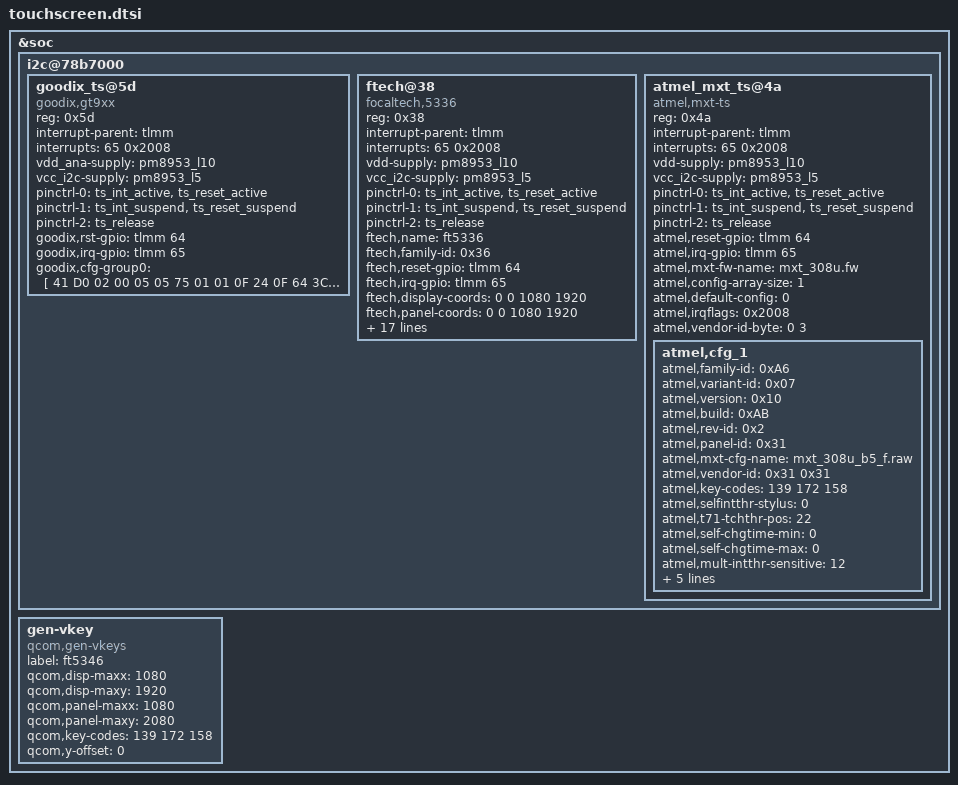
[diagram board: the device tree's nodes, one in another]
&soc{
    i2c@78b7000 { /* BLSP1 QUP3 */
		/delete-node/ synaptics@4b;
		goodix_ts@5d {
			compatible = "goodix,gt9xx";
			reg = <0x5d>;	
			interrupt-parent = <&tlmm>;
			interrupts = <65 0x2008>;
			vdd_ana-supply = <&pm8953_l10>;
			vcc_i2c-supply = <&pm8953_l5>;
			pinctrl-names = "pmx_ts_active","pmx_ts_suspend",
                        "pmx_ts_release";
                        pinctrl-0 = <&ts_int_active &ts_reset_active>;
                        pinctrl-1 = <&ts_int_suspend &ts_reset_suspend>;
                        pinctrl-2 = <&ts_release>;
			goodix,rst-gpio = <&tlmm 64 0x00>;
			goodix,irq-gpio = <&tlmm 65 0x2008>;
			goodix,cfg-group0 = [
				41 D0 02 00 05 05 75 01 01 0F 24 
				0F 64 3C 03 05 00 00 00 02 00 00 
				00 16 19 1C 14 8C 0E 0E 24 00 31 
				0D 00 00 00 83 33 1D 00 41 00 00 
				00 00 00 08 0A 00 2B 1C 3C 94 D5 
				03 08 00 00 04 93 1E 00 82 23 00 
				74 29 00 69 2F 00 5F 37 00 5F 20 
				40 60 00 F0 40 30 55 50 27 00 00 
				00 00 00 00 00 00 00 00 00 00 00 
				00 00 00 00 00 00 00 14 19 00 00 
				50 50 02 04 06 08 0A 0C 0E 10 12 
				14 16 18 1A 1C 00 00 00 00 00 00 
				00 00 00 00 00 00 00 00 00 00 1D 
				1E 1F 20 21 22 24 26 28 29 2A 1C 
				18 16 14 13 12 10 0F 0C 0A 08 06 
				04 02 00 00 00 00 00 00 00 00 00 
				00 00 00 00 00 00 00 00 9C 01];
		};
		ftech@38 {
			compatible = "focaltech,5336";
			reg = <0x38>;
			interrupt-parent = <&tlmm>;
			interrupts = <65 0x2008>;
			vdd-supply = <&pm8953_l10>;
			vcc_i2c-supply = <&pm8953_l5>;
			/* pins used by touchscreen */
			pinctrl-names = "pmx_ts_active","pmx_ts_suspend",
				"pmx_ts_release";
			pinctrl-0 = <&ts_int_active &ts_reset_active>;
			pinctrl-1 = <&ts_int_suspend &ts_reset_suspend>;
			pinctrl-2 = <&ts_release>;
			ftech,name = "ft5336";
			ftech,family-id = <0x36>;
			ftech,reset-gpio = <&tlmm 64 0x00>;
			ftech,irq-gpio = <&tlmm 65 0x2008>;
			ftech,display-coords = <0 0 1080 1920>;
			ftech,panel-coords = <0 0 1080 1920>;
			/*ftech,button-map= <139 102 158>;*/
			ftech,virtual-key1 = <139 180 2000>;/*menu*/
			ftech,virtual-key2 = <172 540 2000>;/*home*/
			ftech,virtual-key3 = <158 900 2000>;/*back*/
			ftech,no-force-update;
			ftech,i2c-pull-up;
			ftech,group-id = <1>;
			ftech,hard-reset-delay-ms = <20>;
			ftech,soft-reset-delay-ms = <200>;
			ftech,num-max-touches = <10>;
			ftech,fw-delay-aa-ms = <30>;
			ftech,fw-delay-55-ms = <30>;
			ftech,fw-upgrade-id1 = <0x79>;
			ftech,fw-upgrade-id2 = <0x18>;
			ftech,fw-delay-readid-ms = <10>;
			ftech,fw-delay-era-flsh-ms = <2000>;
			ftech,fw-auto-cal;
			ftech,ignore-id-check;
		};
		atmel_mxt_ts@4a {
		compatible = "atmel,mxt-ts";
		reg = <0x4a>;
		interrupt-parent = <&tlmm>;
		interrupts = <65 0x2008>;
		vdd-supply = <&pm8953_l10>;
		vcc_i2c-supply = <&pm8953_l5>;
		/* pins used by touchscreen */
		pinctrl-names = "pmx_ts_active","pmx_ts_suspend","pmx_ts_release";
		pinctrl-0 = <&ts_int_active &ts_reset_active>;
		pinctrl-1 = <&ts_int_suspend &ts_reset_suspend>;
		pinctrl-2 = <&ts_release>;
		atmel,reset-gpio = <&tlmm 64 0x0>;
		atmel,irq-gpio = <&tlmm 65 0x2008>;
		atmel,mxt-fw-name = "mxt_308u.fw";
		atmel,config-array-size = <1>;
		atmel,default-config = <0>;
		atmel,irqflags = <0x2008>;
		atmel,vendor-id-byte = /bits/ 8 <0 3>;
		atmel,cfg_1 {
			atmel,family-id = <0xA6>;
			atmel,variant-id = <0x07>;
			atmel,version = <0x10>;
			atmel,build = <0xAB>;
			atmel,rev-id = <0x2>;
			atmel,panel-id = <0x31>;
			atmel,mxt-cfg-name = "mxt_308u_b5_f.raw";
			atmel,vendor-id = /bits/ 8 <0x31 0x31>; /* Biel HW ver 1 */
			atmel,key-codes = <139 172 158>;
			atmel,selfintthr-stylus = <0>;
			atmel,t71-tchthr-pos = <22>;
			atmel,self-chgtime-min = <0>;
			atmel,self-chgtime-max = <0>;
			atmel,mult-intthr-sensitive = <12>;
			atmel,mult-intthr-not-sensitive = <17>;
			atmel,atchthr-sensitive = <6>;
			atmel,mult-tchthr-sensitive = <0>;
			atmel,mult-tchthr-not-sensitive = <0>;
			atmel,wake-up-self-adcx = <16>;
			};
		};
	};
	gen-vkey {
		compatible = "qcom,gen-vkeys";
		label = "ft5346";
		qcom,disp-maxx = <1080>;
		qcom,disp-maxy = <1920>;
		qcom,panel-maxx = <1080>;
		qcom,panel-maxy = <2080>;
		qcom,key-codes = <139 172 158>;
		qcom,y-offset = <0>;
	};
};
